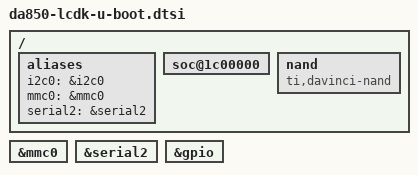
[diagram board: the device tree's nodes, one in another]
// SPDX-License-Identifier: GPL-2.0+
/*
 * da850-lcdk U-Boot Additions
 *
 * Copyright (C) 2018 Texas Instruments Incorporated - https://www.ti.com/
 */

/ {
	aliases {
		i2c0 = &i2c0;
		mmc0 = &mmc0;
		serial2 = &serial2;
	};

	soc@1c00000 {
		bootph-pre-ram;
	};

	nand {
		compatible = "ti,davinci-nand";
	};
};

&mmc0 {
	bootph-pre-ram;
};

&serial2 {
	bootph-pre-ram;
};

&gpio {
	bootph-pre-ram;
};
